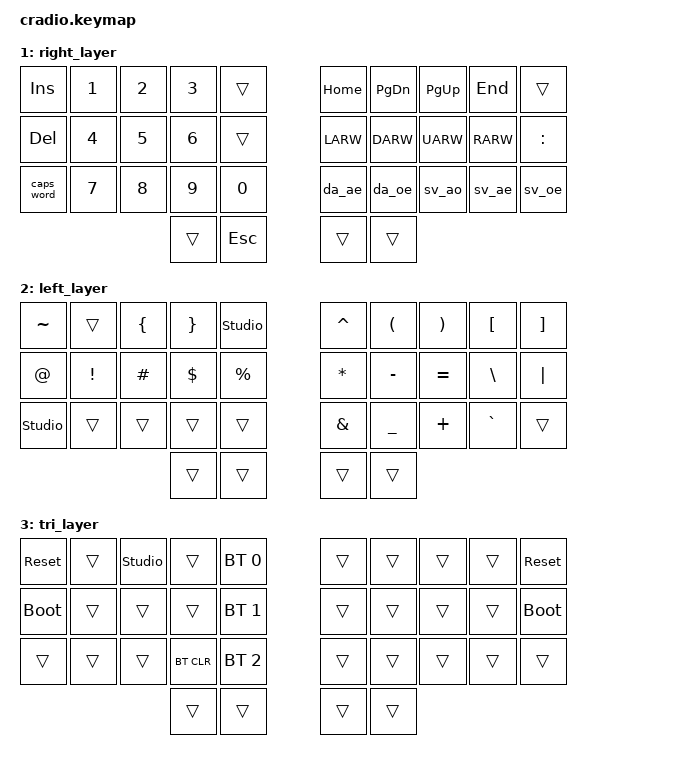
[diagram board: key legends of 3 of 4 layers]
// Copyright (c) 2022 The ZMK Contributors
// SPDX-License-Identifier: MIT

#include <behaviors.dtsi>
#include <dt-bindings/zmk/keys.h>
#include <dt-bindings/zmk/bt.h>

// International umlauts, see https://github.com/urob/zmk-helpers/tree/main?tab=readme-ov-file
// NB! On Mac OS this requires setting the input method to "Unicode Hex Input"
// On windows, install "WinCompose"
#define HOST_OS 2
#include "zmk-helpers/helper.h"
#include "zmk-helpers/key-labels/34.h" // 34 key-position labels
#include "zmk-helpers/unicode-chars/swedish.dtsi" // Source Swe for å ä ö unicode-chars
#include "zmk-helpers/unicode-chars/danish.dtsi" //  Source Danish for æ, ø unicode chars

// Home row mods macro
#define HRML(k1,k2,k3,k4) &ht LSHFT k1  &ht LALT k2  &ht LCTRL k3  &ht LGUI k4
#define HRMR(k1,k2,k3,k4) &ht RGUI k1  &ht RCTRL k2  &ht RALT k3  &ht RSHFT k4

#define DEFAULT 0
#define RGT 1
#define LFT 2
#define TRI 3

// Press both left thumb keys together for dictation / voice command.
ZMK_COMBO(handy_voice, &kp C_VOICE_COMMAND, LH1 LH0, DEFAULT, 60)

/ {
    behaviors {
        ht: hold_tap { 
            
            label = "hold_tap";
            compatible = "zmk,behavior-hold-tap";
            #binding-cells = <2>;
            flavor = "tap-preferred";
            tapping-term-ms = <220>;
            quick-tap-ms = <150>;
            require-prior-idle-ms = <100>;
            bindings = <&kp>, <&kp>;
        };
    };

    conditional_layers {
        compatible = "zmk,conditional-layers";
        tri_layer {
            if-layers = <RGT LFT>;
            then-layer = <TRI>;
        };
    };

    keymap {
        compatible = "zmk,keymap";
        default_layer {
            bindings = <
        //╭──────────┬──────────┬──────────┬──────────┬──────────╮   ╭──────────┬──────────┬──────────┬──────────┬──────────╮
        //│  Q       │  W       │  F       │  P       │  B       │   │  J       │  L       │  U       │  Y       │  ; :     │
            &kp Q      &kp W      &kp F      &kp P      &kp B          &kp J      &kp L      &kp U      &kp Y      &kp SEMI
        //├──────────┼──────────┼──────────┼──────────┼──────────┤   ├──────────┼──────────┼──────────┼──────────┼──────────┤
        //│  A       │  R       │  S       │  T       │  G       │   │  M       │  N       │  E       │  I       │ O        │
            HRML(A,        R,         S,         T)     &kp G          &kp M      HRMR(N,        E,         I,        O)
        //├──────────┼──────────┼──────────┼──────────┼──────────┤   ├──────────┼──────────┼──────────┼──────────┼──────────┤
        //│  Z       │  X       │  C       │  D       │  V       │   │  K       │  H       │ , <      │ . >      │ / ?      │
            &kp Z      &kp X      &kp C      &kp D      &kp V          &kp K      &kp H      &kp COMMA  &kp DOT    &kp FSLH
        //╰──────────┴──────────┴──────────┼──────────┼──────────┤   ├──────────┼──────────┼──────────┴──────────┴──────────╯
                                            &lt LFT TAB   &kp SPACE     &kp ENTER  &lt RGT BSPC
        //                                 ╰──────────┴──────────╯   ╰──────────┴──────────╯
            >;
        };

        right_layer {
            bindings = <
        //╭──────────┬──────────┬──────────┬──────────┬──────────╮   ╭──────────┬──────────┬──────────┬──────────┬──────────╮
        //│ INSERT   │  1       │  2       │  3       │          │   │ HOME     │ PAGE DN  │ PAGE UP  │ END      │          │
            &kp INS    &kp N1     &kp N2     &kp N3     &trans         &kp HOME   &kp PG_DN  &kp PG_UP  &kp END    &trans
        //├──────────┼──────────┼──────────┼──────────┼──────────┤   ├──────────┼──────────┼──────────┼──────────┼──────────┤
        //│ DELETE   │  4       │  5       │  6       │          │   │ LEFT     │ DOWN     │ UP       │ RIGHT    │  :       │
            &kp DEL    &kp N4     &kp N5     &kp N6     &trans         &kp LARW   &kp DARW   &kp UARW   &kp RARW   &kp COLON
        //├──────────┼──────────┼──────────┼──────────┼──────────┤   ├──────────┼──────────┼──────────┼──────────┼──────────┤
        //│ CAPS     │  7       │  8       │  9       │  0       │   │  Æ       │ Ø        │ Å        │  Ä       │  Ö       │
           &caps_word  &kp N7     &kp N8     &kp N9     &kp N0         &da_ae     &da_oe     &sv_ao      &sv_ae     &sv_oe
        //╰──────────┴──────────┴──────────┼──────────┼──────────┤   ├──────────┼──────────┼──────────┴──────────┴──────────╯
                                             &trans     &kp ESC        &trans     &trans
        //                                 ╰──────────┴──────────╯   ╰──────────┴──────────╯
            >;
        };

        left_layer {
            bindings = <
        //╭──────────┬──────────┬──────────┬──────────┬──────────╮   ╭──────────┬──────────┬──────────┬──────────┬──────────╮
        //│ ~        │          │  {       │  }       │ studio   │  ^       │  (       │  )       │  [       │  ]       │
            &kp TILDE   &trans     &kp LBRC   &kp RBRC &studio_unlock &kp CARET  &kp LPAR   &kp RPAR  &kp LBKT  &kp RBKT   
        //├──────────┼──────────┼──────────┼──────────┼──────────┤   ├──────────┼──────────┼──────────┼──────────┼──────────┤
        //│  @       │ !        │ #        │ $        │ %        │   │  *       │  -       │  =       │  \       │  │       │
             &kp AT    &kp EXCL   &kp HASH   &kp DLLR   &kp PRCNT      &kp ASTRK  &kp MINUS  &kp EQUAL  &kp BSLH   &kp PIPE
        //├──────────┼──────────┼──────────┼──────────┼──────────┤   ├──────────┼──────────┼──────────┼──────────┼──────────┤
        //│          │          │          │          │          │   │  &       │  _       │  +       │  `       │          │
          &studio_unlock     &trans     &trans     &trans     &trans          &kp AMPS   &kp UNDER  &kp PLUS   &kp GRAVE   &trans
        //╰──────────┴──────────┴──────────┼──────────┼──────────┤   ├──────────┼──────────┼──────────┴──────────┴──────────╯
                                             &trans     &trans         &trans     &trans
        //                                 ╰──────────┴──────────╯   ╰──────────┴──────────╯
            >;
        };

        tri_layer {
            bindings = <
        //╭──────────┬──────────┬──────────┬──────────┬──────────╮   ╭──────────┬──────────┬──────────┬──────────┬──────────╮
        //│ RESET    │          │ Studio   │          │PROFILE 0 │   │          │          │          │          │  RESET   │
           &sys_reset  &trans  &studio_unlock  &trans  &bt BT_SEL 0    &trans     &trans     &trans     &trans    &sys_reset
        //├──────────┼──────────┼──────────┼──────────┼──────────┤   ├──────────┼──────────┼──────────┼──────────┼──────────┤
        //│BOOTLOADER│          │          │          │PROFILE 1 │   │          │          │          │          │BOOTLOADER│
          &bootloader  &trans     &trans     &trans    &bt BT_SEL 1    &trans     &trans     &trans     &trans    &bootloader
        //├──────────┼──────────┼──────────┼──────────┼──────────┤   ├──────────┼──────────┼──────────┼──────────┼──────────┤
        //│          │          │          │ CLEAR BT │PROFILE 2 │   │          │          │          │          │          │
            &trans     &trans     &trans    &bt BT_CLR &bt BT_SEL 2    &trans     &trans     &trans     &trans     &trans
        //╰──────────┴──────────┴──────────┼──────────┼──────────┤   ├──────────┼──────────┼──────────┴──────────┴──────────╯
                                             &trans     &trans         &trans     &trans
        //                                 ╰──────────┴──────────╯   ╰──────────┴──────────╯
            >;
        };

        extra1 {
            status = "reserved";
        };
        extra2 {
            status = "reserved";
        };
    };
};
